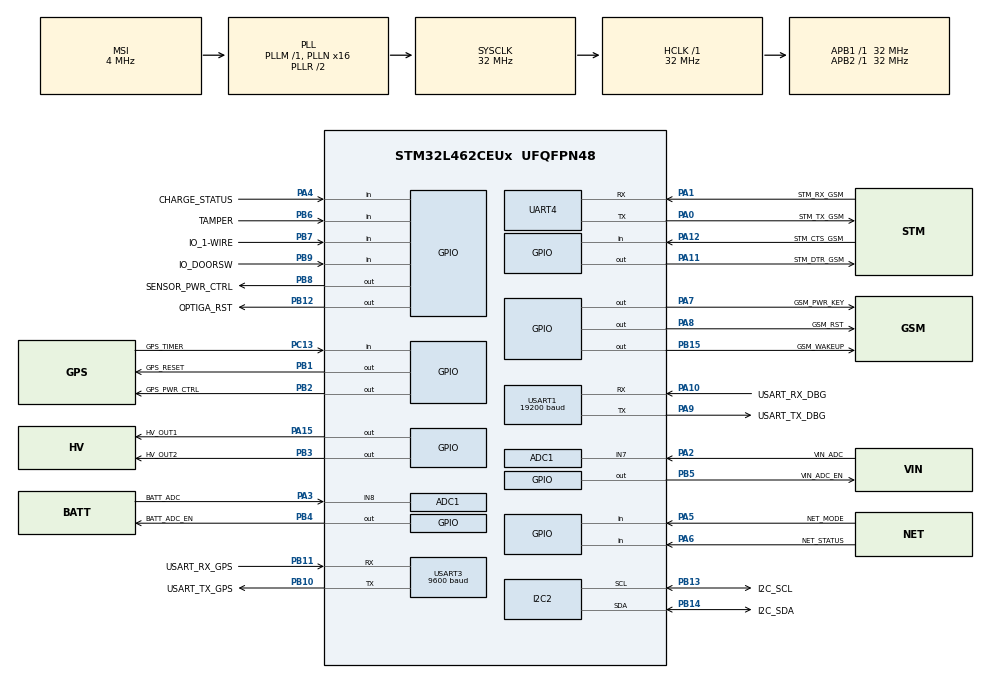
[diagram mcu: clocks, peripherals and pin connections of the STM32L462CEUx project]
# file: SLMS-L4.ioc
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ADC1.Channel-2\#ChannelRegularConversion=ADC_CHANNEL_7
ADC1.ContinuousConvMode=DISABLE
ADC1.EnableRegularConversion=ENABLE
ADC1.NbrOfConversionFlag=1
ADC1.OffsetNumber-2\#ChannelRegularConversion=ADC_OFFSET_NONE
ADC1.Rank-2\#ChannelRegularConversion=1
ADC1.SamplingTime-2\#ChannelRegularConversion=ADC_SAMPLETIME_640CYCLES_5
ADC1.master=1
I2C2.Timing=0x00707CBB
IWDG.Prescaler=IWDG_PRESCALER_256
Mcu.Family=STM32L4
Mcu.Name=STM32L462CEUx
Mcu.Package=UFQFPN48
NVIC.PriorityGroup=NVIC_PRIORITYGROUP_4
NVIC.UART4_IRQn=true\:1\:0\:true\:false\:true\:true\:true
NVIC.USART1_IRQn=true\:1\:0\:true\:false\:true\:true\:true
NVIC.USART3_IRQn=true\:2\:0\:true\:false\:true\:true\:true
PA0.GPIO_Label=STM_TX_GSM
PA0.Mode=Asynchronous
PA0.Signal=UART4_TX
PA1.GPIO_Label=STM_RX_GSM
PA1.GPIO_PuPd=GPIO_PULLUP
PA1.Mode=Asynchronous
PA1.Signal=UART4_RX
PA10.GPIO_Label=USART_RX_DBG
PA10.GPIO_PuPd=GPIO_PULLDOWN
PA10.Mode=Asynchronous
PA10.Signal=USART1_RX
PA11.GPIO_Label=STM_DTR_GSM
PA11.Signal=GPIO_Output
PA12.GPIO_Label=STM_CTS_GSM
PA12.Signal=GPIO_Input
PA13\ (JTMS/SWDIO).Mode=Serial_Wire
PA13\ (JTMS/SWDIO).Signal=SYS_JTMS-SWDIO
PA14\ (JTCK/SWCLK).Mode=Serial_Wire
PA14\ (JTCK/SWCLK).Signal=SYS_JTCK-SWCLK
PA15\ (JTDI).GPIO_Label=HV_OUT1
PA15\ (JTDI).Signal=GPIO_Output
PA2.GPIO_Label=VIN_ADC
PA2.Signal=SharedAnalog_PA2
PA3.GPIO_Label=BATT_ADC
PA3.Signal=SharedAnalog_PA3
PA4.GPIO_Label=CHARGE_STATUS
PA4.Signal=GPIO_Input
PA5.GPIO_Label=NET_MODE
PA5.Signal=GPIO_Input
PA6.GPIO_Label=NET_STATUS
PA6.Signal=GPIO_Input
PA7.GPIO_Label=GSM_PWR_KEY
PA7.Signal=GPIO_Output
PA8.GPIO_Label=GSM_RST
PA8.Signal=GPIO_Output
PA9.GPIO_Label=USART_TX_DBG
PA9.Mode=Asynchronous
PA9.Signal=USART1_TX
PB1.GPIO_Label=GPS_RESET
PB1.Signal=GPIO_Output
PB10.GPIO_Label=USART_TX_GPS
PB10.Mode=Asynchronous
PB10.Signal=USART3_TX
PB11.GPIO_Label=USART_RX_GPS
PB11.GPIO_PuPd=GPIO_PULLUP
PB11.Mode=Asynchronous
PB11.Signal=USART3_RX
PB12.GPIO_Label=OPTIGA_RST
PB12.Signal=GPIO_Output
PB13.GPIO_Label=I2C_SCL
PB13.Mode=I2C
PB13.Signal=I2C2_SCL
PB14.GPIO_Label=I2C_SDA
PB14.Mode=I2C
PB14.Signal=I2C2_SDA
PB15.GPIO_Label=GSM_WAKEUP
PB15.Signal=GPIO_Output
PB2.GPIO_Label=GPS_PWR_CTRL
PB2.Signal=GPIO_Output
PB3\ (JTDO/TRACESWO).GPIO_Label=HV_OUT2
PB3\ (JTDO/TRACESWO).Signal=GPIO_Output
PB4\ (NJTRST).GPIO_Label=BATT_ADC_EN
PB4\ (NJTRST).Signal=GPIO_Output
PB5.GPIO_Label=VIN_ADC_EN
PB5.Signal=GPIO_Output
PB6.GPIO_Label=TAMPER
PB6.Signal=GPIO_Input
PB7.GPIO_Label=IO_1-WIRE
PB7.Signal=GPIO_Input
PB8.GPIO_Label=SENSOR_PWR_CTRL
PB8.Signal=GPIO_Output
PB9.GPIO_Label=IO_DOORSW
PB9.Signal=GPIO_Input
PC13.GPIO_Label=GPS_TIMER
PC13.Signal=GPIO_Input
PC14-OSC32_IN\ (PC14).Mode=LSE-External-Oscillator
PC14-OSC32_IN\ (PC14).Signal=RCC_OSC32_IN
PC15-OSC32_OUT\ (PC15).Mode=LSE-External-Oscillator
PC15-OSC32_OUT\ (PC15).Signal=RCC_OSC32_OUT
ProjectManager.HeapSize=0x200
ProjectManager.StackSize=0x400
ProjectManager.TargetToolchain=STM32CubeIDE
RCC.ADCFreq_Value=32000000
RCC.AHBFreq_Value=32000000
RCC.APB1Freq_Value=32000000
RCC.APB1TimFreq_Value=32000000
RCC.APB2Freq_Value=32000000
RCC.APB2TimFreq_Value=32000000
RCC.CortexFreq_Value=32000000
RCC.HCLKFreq_Value=32000000
RCC.HSE_VALUE=8000000
RCC.HSI48_VALUE=48000000
RCC.HSI_VALUE=16000000
RCC.MSI_VALUE=4000000
RCC.PLLN=16
RCC.PLLSAI1N=16
RCC.RTCClockSelection=RCC_RTCCLKSOURCE_LSE
RCC.SYSCLKFreq_VALUE=32000000
RCC.SYSCLKSource=RCC_SYSCLKSOURCE_PLLCLK
RCC.USBFreq_Value=32000000
RCC.VCOOutputFreq_Value=64000000
SH.SharedAnalog_PA2.0=GPIO_Analog
SH.SharedAnalog_PA2.1=ADC1_IN7,IN7-Single-Ended
SH.SharedAnalog_PA3.0=GPIO_Analog
SH.SharedAnalog_PA3.1=ADC1_IN8,IN8-Single-Ended
TIM1.AutoReloadPreload=TIM_AUTORELOAD_PRELOAD_ENABLE
TIM1.Period=16000-1
TIM1.Prescaler=10000-1
USART1.BaudRate=19200
USART1.RxPinLevelInvertParam=ADVFEATURE_RXINV_ENABLE
USART1.TxPinLevelInvertParam=ADVFEATURE_TXINV_ENABLE
USART1.VirtualMode-Asynchronous=VM_ASYNC
USART3.BaudRate=9600
USART3.VirtualMode-Asynchronous=VM_ASYNC
VP_IWDG_VS_IWDG.Mode=IWDG_Activate
VP_RTC_VS_RTC_Activate.Mode=RTC_Enabled
VP_TIM1_VS_ClockSourceINT.Mode=Internal
board=custom

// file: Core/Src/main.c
/* USER CODE BEGIN Header */
/**
  ******************************************************************************
  * @file           : main.c
  * @brief          : Main program body
  ******************************************************************************
  * @attention
  *
  * <h2><center>&copy; Copyright (c) 2020 STMicroelectronics.
  * All rights reserved.</center></h2>
  *
  * This software component is licensed by ST under BSD 3-Clause license,
  * the "License"; You may not use this file except in compliance with the
  * License. You may obtain a copy of the License at:
  *                        opensource.org/licenses/BSD-3-Clause
  *
  ******************************************************************************
  */
/* USER CODE END Header */

#include "main.h"
#include "adc.h"
#include "i2c.h"
#include "iwdg.h"
#include "rtc.h"
#include "tim.h"
#include "usart.h"
#include "gpio.h"

/* USER CODE BEGIN Includes */
#include "proc.h"
/* USER CODE END Includes */

void SystemClock_Config(void);

int main(void)
{
  /* USER CODE BEGIN 1 */
  setbuf(stdout, NULL);
  /* USER CODE END 1 */

  /* MCU Configuration--------------------------------------------------------*/

  /* Reset of all peripherals, Initializes the Flash interface and the Systick. */
  HAL_Init();

  /* Configure the system clock */
  SystemClock_Config();

  /* Initialize all configured peripherals */
  MX_GPIO_Init();
  MX_ADC1_Init();
  MX_I2C2_Init();
  MX_UART4_Init();
  MX_USART1_UART_Init();
  MX_USART3_UART_Init();
  MX_RTC_Init();
  MX_TIM1_Init();
  MX_IWDG_Init();
  /* USER CODE BEGIN 2 */
  Setup();
  /* USER CODE END 2 */

  /* Infinite loop */
  /* USER CODE BEGIN WHILE */
  while (1)
  {
	Loop();
    /* USER CODE END WHILE */

  }
}

void SystemClock_Config(void)
{
  RCC_OscInitTypeDef RCC_OscInitStruct = {0};
  RCC_ClkInitTypeDef RCC_ClkInitStruct = {0};
  RCC_PeriphCLKInitTypeDef PeriphClkInit = {0};

  /** Configure LSE Drive Capability
  */
  HAL_PWR_EnableBkUpAccess();
  __HAL_RCC_LSEDRIVE_CONFIG(RCC_LSEDRIVE_LOW);
  /** Initializes the CPU, AHB and APB busses clocks
  */
  RCC_OscInitStruct.OscillatorType = RCC_OSCILLATORTYPE_LSI|RCC_OSCILLATORTYPE_LSE
                              |RCC_OSCILLATORTYPE_MSI;
  RCC_OscInitStruct.LSEState = RCC_LSE_ON;
  RCC_OscInitStruct.LSIState = RCC_LSI_ON;
  RCC_OscInitStruct.MSIState = RCC_MSI_ON;
  RCC_OscInitStruct.MSICalibrationValue = 0;
  RCC_OscInitStruct.MSIClockRange = RCC_MSIRANGE_6;
  RCC_OscInitStruct.PLL.PLLState = RCC_PLL_ON;
  RCC_OscInitStruct.PLL.PLLSource = RCC_PLLSOURCE_MSI;
  RCC_OscInitStruct.PLL.PLLM = 1;
  RCC_OscInitStruct.PLL.PLLN = 16;
  RCC_OscInitStruct.PLL.PLLP = RCC_PLLP_DIV7;
  RCC_OscInitStruct.PLL.PLLQ = RCC_PLLQ_DIV2;
  RCC_OscInitStruct.PLL.PLLR = RCC_PLLR_DIV2;
  if (HAL_RCC_OscConfig(&RCC_OscInitStruct) != HAL_OK)
  {
    Error_Handler();
  }
  /** Initializes the CPU, AHB and APB busses clocks
  */
  RCC_ClkInitStruct.ClockType = RCC_CLOCKTYPE_HCLK|RCC_CLOCKTYPE_SYSCLK
                              |RCC_CLOCKTYPE_PCLK1|RCC_CLOCKTYPE_PCLK2;
  RCC_ClkInitStruct.SYSCLKSource = RCC_SYSCLKSOURCE_PLLCLK;
  RCC_ClkInitStruct.AHBCLKDivider = RCC_SYSCLK_DIV1;
  RCC_ClkInitStruct.APB1CLKDivider = RCC_HCLK_DIV1;
  RCC_ClkInitStruct.APB2CLKDivider = RCC_HCLK_DIV1;

  if (HAL_RCC_ClockConfig(&RCC_ClkInitStruct, FLASH_LATENCY_1) != HAL_OK)
  {
    Error_Handler();
  }
  PeriphClkInit.PeriphClockSelection = RCC_PERIPHCLK_RTC|RCC_PERIPHCLK_USART1
                              |RCC_PERIPHCLK_USART3|RCC_PERIPHCLK_UART4
                              |RCC_PERIPHCLK_I2C2|RCC_PERIPHCLK_ADC;
  PeriphClkInit.Usart1ClockSelection = RCC_USART1CLKSOURCE_PCLK2;
  PeriphClkInit.Usart3ClockSelection = RCC_USART3CLKSOURCE_PCLK1;
  PeriphClkInit.Uart4ClockSelection = RCC_UART4CLKSOURCE_PCLK1;
  PeriphClkInit.I2c2ClockSelection = RCC_I2C2CLKSOURCE_PCLK1;
  PeriphClkInit.AdcClockSelection = RCC_ADCCLKSOURCE_PLLSAI1;
  PeriphClkInit.RTCClockSelection = RCC_RTCCLKSOURCE_LSE;
  PeriphClkInit.PLLSAI1.PLLSAI1Source = RCC_PLLSOURCE_MSI;
  PeriphClkInit.PLLSAI1.PLLSAI1M = 1;
  PeriphClkInit.PLLSAI1.PLLSAI1N = 16;
  PeriphClkInit.PLLSAI1.PLLSAI1P = RCC_PLLP_DIV7;
  PeriphClkInit.PLLSAI1.PLLSAI1Q = RCC_PLLQ_DIV2;
  PeriphClkInit.PLLSAI1.PLLSAI1R = RCC_PLLR_DIV2;
  PeriphClkInit.PLLSAI1.PLLSAI1ClockOut = RCC_PLLSAI1_ADC1CLK;
  if (HAL_RCCEx_PeriphCLKConfig(&PeriphClkInit) != HAL_OK)
  {
    Error_Handler();
  }
  /** Configure the main internal regulator output voltage
  */
  if (HAL_PWREx_ControlVoltageScaling(PWR_REGULATOR_VOLTAGE_SCALE1) != HAL_OK)
  {
    Error_Handler();
  }
  /** Enable MSI Auto calibration
  */
  HAL_RCCEx_EnableMSIPLLMode();
}

/* USER CODE BEGIN 4 */
void HAL_TIM_PeriodElapsedCallback(TIM_HandleTypeDef *htim){

}
/* USER CODE END 4 */

void Error_Handler(void)
{
}

/************************ (C) COPYRIGHT STMicroelectronics *****END OF FILE****/
